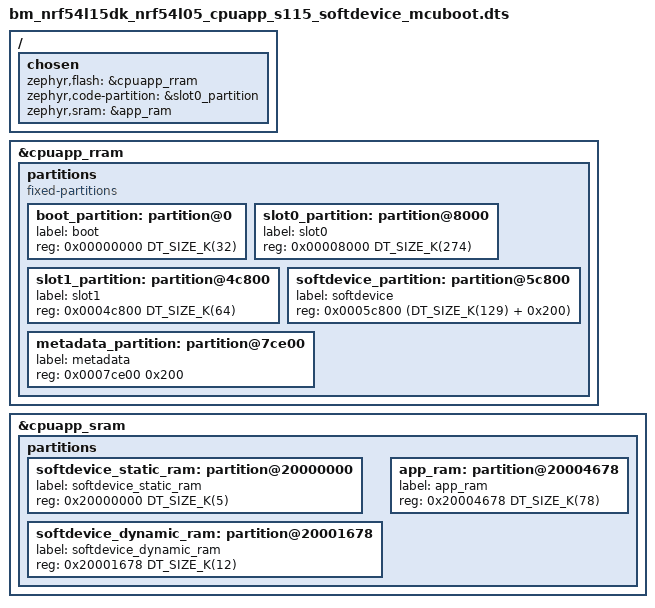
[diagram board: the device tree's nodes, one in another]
/*
 * Copyright (c) 2025 Nordic Semiconductor ASA
 *
 * SPDX-License-Identifier: LicenseRef-Nordic-5-Clause
 */

/dts-v1/;

#include <nordic/nrf54l05_cpuapp.dtsi>
#include "bm_nrf54l15dk_nrf54l05_cpuapp_common.dtsi"

/ {
	chosen {
		zephyr,flash = &cpuapp_rram;
		zephyr,code-partition = &slot0_partition;
		zephyr,sram = &app_ram;
	};
};

&cpuapp_rram {
	status = "okay";

	partitions {
		compatible = "fixed-partitions";
		#address-cells = <1>;
		#size-cells = <1>;

		boot_partition: partition@0 {
			label = "boot";
			reg = <0x00000000 DT_SIZE_K(32)>;
		};

		slot0_partition: partition@8000 {
			label = "slot0";
			reg = <0x00008000 DT_SIZE_K(274)>;
		};

		slot1_partition: partition@4c800 {
			label = "slot1";
			reg = <0x0004c800 DT_SIZE_K(64)>;
		};

		softdevice_partition: partition@5c800 {
			label = "softdevice";
			reg = <0x0005c800 (DT_SIZE_K(129) + 0x200)>;
		};

		metadata_partition: partition@7ce00 {
			label = "metadata";
			reg = <0x0007ce00 0x200>;
		};
	};
};

&cpuapp_sram {
	status = "okay";

	partitions {
		#address-cells = <1>;
		#size-cells = <1>;

		softdevice_static_ram: partition@20000000 {
			label = "softdevice_static_ram";
			reg = <0x20000000 DT_SIZE_K(5)>;
		};

		softdevice_dynamic_ram: partition@20001678 {
			label = "softdevice_dynamic_ram";
			reg = <0x20001678 DT_SIZE_K(12)>;
		};

		app_ram: partition@20004678 {
			label = "app_ram";
			reg = <0x20004678 DT_SIZE_K(78)>;
		};
	};
};
